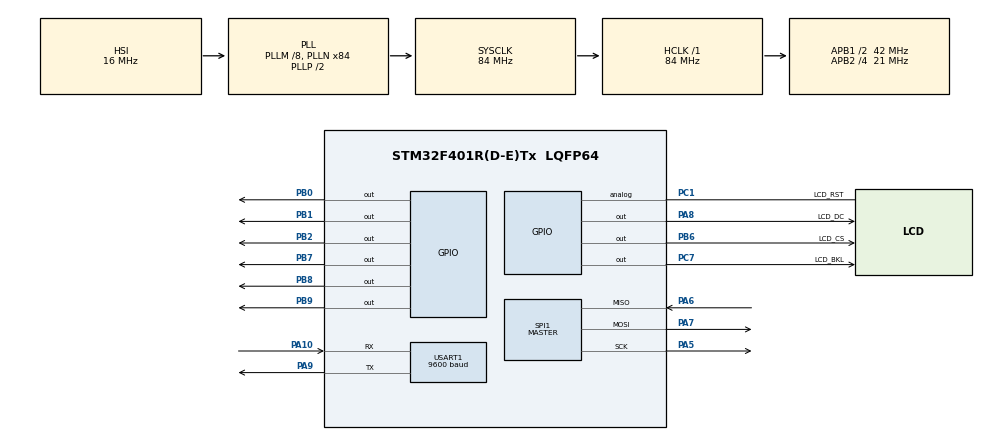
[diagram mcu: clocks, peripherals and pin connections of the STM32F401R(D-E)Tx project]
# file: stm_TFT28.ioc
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Mcu.Family=STM32F4
PA6.Mode=Full_Duplex_Master
RCC.CortexFreq_Value=84000000
SPI1.VirtualType=VM_MASTER
USART1.BaudRate=9600
PB6.GPIO_Label=LCD_CS
RCC.SYSCLKSource=RCC_SYSCLKSOURCE_PLLCLK
ProjectManager.StackSize=0x400
SPI1.CLKPolarity=SPI_POLARITY_HIGH
PH0\ -\ OSC_IN.Signal=RCC_OSC_IN
SPI1.Direction=SPI_DIRECTION_2LINES
PB1.GPIO_PuPd=GPIO_PULLDOWN
RCC.HCLKFreq_Value=84000000
RCC.APB2TimFreq_Value=42000000
PB6.Signal=GPIO_Output
PC7.Signal=GPIO_Output
RCC.AHBFreq_Value=84000000
RCC.HSE_VALUE=25000000
PB2.Signal=GPIO_Output
PA6.GPIO_PuPd=GPIO_PULLUP
PA5.GPIO_PuPd=GPIO_PULLUP
PB7.Signal=GPIO_Output
PA8.Signal=GPIO_Output
PB2.GPIO_PuPd=GPIO_PULLDOWN
TIM9.Prescaler=21000
Mcu.Package=LQFP64
PB9.Signal=GPIO_Output
PB1.Signal=GPIO_Output
PA6.Signal=SPI1_MISO
PA10.Signal=USART1_RX
PB9.GPIO_PuPd=GPIO_PULLDOWN
RCC.APB2CLKDivider=RCC_HCLK_DIV4
RCC.APB1TimFreq_Value=84000000
PA6.GPIO_Speed=GPIO_SPEED_FREQ_HIGH
NVIC.USART1_IRQn=true\:0\:0\:false\:false\:true\:true\:true
SPI1.BaudRatePrescaler=SPI_BAUDRATEPRESCALER_16
PA8.GPIO_Speed=GPIO_SPEED_FREQ_HIGH
TIM9.Period=1
PA5.Mode=Full_Duplex_Master
PB7.GPIO_PuPd=GPIO_PULLDOWN
PA7.Mode=Full_Duplex_Master
PA10.Mode=Asynchronous
PB6.GPIO_PuPd=GPIO_PULLUP
PH1\ -\ OSC_OUT.Mode=HSE-External-Oscillator
PB8.GPIO_PuPd=GPIO_PULLDOWN
SPI1.CLKPhase=SPI_PHASE_2EDGE
RCC.APB1CLKDivider=RCC_HCLK_DIV2
PA0-WKUP.Signal=SYS_WKUP
PA0-WKUP.Mode=SYS_WakeUp0
PA9.Mode=Asynchronous
PH0\ -\ OSC_IN.Mode=HSE-External-Oscillator
PA8.GPIO_Label=LCD_DC
ProjectManager.TargetToolchain=SW4STM32
PA9.Signal=USART1_TX
PC7.GPIO_PuPd=GPIO_PULLUP
RCC.LSE_VALUE=32768
PA7.GPIO_PuPd=GPIO_PULLUP
PA5.Signal=SPI1_SCK
PH1\ -\ OSC_OUT.Signal=RCC_OSC_OUT
board=stm_TFT28
PC7.GPIO_Speed=GPIO_SPEED_FREQ_HIGH
RCC.VCOOutputFreq_Value=168000000
PA7.GPIO_Speed=GPIO_SPEED_FREQ_HIGH
VP_TIM9_VS_ClockSourceINT.Mode=Internal
RCC.APB2Freq_Value=21000000
SPI1.CRCCalculation=SPI_CRCCALCULATION_DISABLE
SPI1.Mode=SPI_MODE_MASTER
PC1.GPIO_Label=LCD_RST
Mcu.Name=STM32F401R(D-E)Tx
TIM9.ClockDivision=TIM_CLOCKDIVISION_DIV1
NVIC.TIM1_BRK_TIM9_IRQn=true\:0\:0\:false\:false\:true\:true\:true
PC7.GPIO_Label=LCD_BKL
RCC.48MHZClocksFreq_Value=42000000
RCC.SYSCLKFreq_VALUE=84000000
USART1.VirtualMode=VM_ASYNC
ProjectManager.HeapSize=0x200
RCC.HSI_VALUE=16000000
PA8.GPIO_PuPd=GPIO_PULLUP
PA5.GPIO_Speed=GPIO_SPEED_FREQ_HIGH
NVIC.PriorityGroup=NVIC_PRIORITYGROUP_4
RCC.PLLM=8
RCC.PLLN=84
PB8.Signal=GPIO_Output
PB6.GPIO_Speed=GPIO_SPEED_FREQ_HIGH
RCC.APB1Freq_Value=42000000
PB0.Signal=GPIO_Output
PC1.Signal=GPIO_Analog
PB0.GPIO_PuPd=GPIO_PULLDOWN
PA7.Signal=SPI1_MOSI

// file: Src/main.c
/* USER CODE BEGIN Header */
/**
  ******************************************************************************
  * @file           : main.c
  * @brief          : Main program body
  ******************************************************************************
  * @attention
  *
  * <h2><center>&copy; Copyright (c) 2020 STMicroelectronics.
  * All rights reserved.</center></h2>
  *
  * This software component is licensed by ST under BSD 3-Clause license,
  * the "License"; You may not use this file except in compliance with the
  * License. You may obtain a copy of the License at:
  *                        opensource.org/licenses/BSD-3-Clause
  *
  ******************************************************************************
  */
/* USER CODE END Header */

#include "main.h"

/* USER CODE BEGIN Includes */
#include "main_usercode.h"
/* USER CODE END Includes */

SPI_HandleTypeDef hspi1;

TIM_HandleTypeDef htim9;

UART_HandleTypeDef huart1;

/* USER CODE BEGIN PV */
/* Private variables ---------------------------------------------------------*/

/* USER CODE END PV */

void SystemClock_Config(void);
static void MX_GPIO_Init(void);
static void MX_TIM9_Init(void);
static void MX_SPI1_Init(void);
static void MX_USART1_UART_Init(void);
/* USER CODE BEGIN PFP */
/* Private function prototypes -----------------------------------------------*/

/* USER CODE END PFP */

/* USER CODE BEGIN 0 */
uint8_t GL_PROJECT_NAME[]="PROJECT OF EXPERIMENTS WITH ShareWave TFT 2.8 #1\r\n";
/* USER CODE END 0 */

int main(void)
{

  /* MCU Configuration--------------------------------------------------------*/

  /* Reset of all peripherals, Initializes the Flash interface and the Systick. */
  HAL_Init();

  /* Configure the system clock */
  SystemClock_Config();

  /* Initialize all configured peripherals */
  MX_GPIO_Init();
  MX_TIM9_Init();
  MX_SPI1_Init();
  MX_USART1_UART_Init();

  /* Infinite loop */
  /* USER CODE BEGIN WHILE */
  while (1)
  {
    main_usercode();
    /* USER CODE END WHILE */

  }
}

void SystemClock_Config(void)
{
  RCC_OscInitTypeDef RCC_OscInitStruct = {0};
  RCC_ClkInitTypeDef RCC_ClkInitStruct = {0};

  /** Configure the main internal regulator output voltage
  */
  __HAL_RCC_PWR_CLK_ENABLE();
  __HAL_PWR_VOLTAGESCALING_CONFIG(PWR_REGULATOR_VOLTAGE_SCALE2);
  /** Initializes the CPU, AHB and APB busses clocks
  */
  RCC_OscInitStruct.OscillatorType = RCC_OSCILLATORTYPE_HSI;
  RCC_OscInitStruct.HSIState = RCC_HSI_ON;
  RCC_OscInitStruct.HSICalibrationValue = RCC_HSICALIBRATION_DEFAULT;
  RCC_OscInitStruct.PLL.PLLState = RCC_PLL_ON;
  RCC_OscInitStruct.PLL.PLLSource = RCC_PLLSOURCE_HSI;
  RCC_OscInitStruct.PLL.PLLM = 8;
  RCC_OscInitStruct.PLL.PLLN = 84;
  RCC_OscInitStruct.PLL.PLLP = RCC_PLLP_DIV2;
  RCC_OscInitStruct.PLL.PLLQ = 4;
  if (HAL_RCC_OscConfig(&RCC_OscInitStruct) != HAL_OK)
  {
    Error_Handler();
  }
  /** Initializes the CPU, AHB and APB busses clocks
  */
  RCC_ClkInitStruct.ClockType = RCC_CLOCKTYPE_HCLK|RCC_CLOCKTYPE_SYSCLK
                              |RCC_CLOCKTYPE_PCLK1|RCC_CLOCKTYPE_PCLK2;
  RCC_ClkInitStruct.SYSCLKSource = RCC_SYSCLKSOURCE_PLLCLK;
  RCC_ClkInitStruct.AHBCLKDivider = RCC_SYSCLK_DIV1;
  RCC_ClkInitStruct.APB1CLKDivider = RCC_HCLK_DIV2;
  RCC_ClkInitStruct.APB2CLKDivider = RCC_HCLK_DIV4;

  if (HAL_RCC_ClockConfig(&RCC_ClkInitStruct, FLASH_LATENCY_2) != HAL_OK)
  {
    Error_Handler();
  }
}

static void MX_SPI1_Init(void)
{

  /* SPI1 parameter configuration*/
  hspi1.Instance = SPI1;
  hspi1.Init.Mode = SPI_MODE_MASTER;
  hspi1.Init.Direction = SPI_DIRECTION_2LINES;
  hspi1.Init.DataSize = SPI_DATASIZE_8BIT;
  hspi1.Init.CLKPolarity = SPI_POLARITY_HIGH;
  hspi1.Init.CLKPhase = SPI_PHASE_2EDGE;
  hspi1.Init.NSS = SPI_NSS_SOFT;
  hspi1.Init.BaudRatePrescaler = SPI_BAUDRATEPRESCALER_16;
  hspi1.Init.FirstBit = SPI_FIRSTBIT_MSB;
  hspi1.Init.TIMode = SPI_TIMODE_DISABLE;
  hspi1.Init.CRCCalculation = SPI_CRCCALCULATION_DISABLE;
  hspi1.Init.CRCPolynomial = 10;
  if (HAL_SPI_Init(&hspi1) != HAL_OK)
  {
    Error_Handler();
  }

}

static void MX_TIM9_Init(void)
{

  TIM_ClockConfigTypeDef sClockSourceConfig = {0};

  htim9.Instance = TIM9;
  htim9.Init.Prescaler = 21000;
  htim9.Init.CounterMode = TIM_COUNTERMODE_UP;
  htim9.Init.Period = 1;
  htim9.Init.ClockDivision = TIM_CLOCKDIVISION_DIV1;
  htim9.Init.AutoReloadPreload = TIM_AUTORELOAD_PRELOAD_DISABLE;
  if (HAL_TIM_Base_Init(&htim9) != HAL_OK)
  {
    Error_Handler();
  }
  sClockSourceConfig.ClockSource = TIM_CLOCKSOURCE_INTERNAL;
  if (HAL_TIM_ConfigClockSource(&htim9, &sClockSourceConfig) != HAL_OK)
  {
    Error_Handler();
  }

}

static void MX_USART1_UART_Init(void)
{

  huart1.Instance = USART1;
  huart1.Init.BaudRate = 9600;
  huart1.Init.WordLength = UART_WORDLENGTH_8B;
  huart1.Init.StopBits = UART_STOPBITS_1;
  huart1.Init.Parity = UART_PARITY_NONE;
  huart1.Init.Mode = UART_MODE_TX_RX;
  huart1.Init.HwFlowCtl = UART_HWCONTROL_NONE;
  huart1.Init.OverSampling = UART_OVERSAMPLING_16;
  if (HAL_UART_Init(&huart1) != HAL_OK)
  {
    Error_Handler();
  }

}

static void MX_GPIO_Init(void)
{
  GPIO_InitTypeDef GPIO_InitStruct = {0};

  /* GPIO Ports Clock Enable */
  __HAL_RCC_GPIOH_CLK_ENABLE();
  __HAL_RCC_GPIOC_CLK_ENABLE();
  __HAL_RCC_GPIOA_CLK_ENABLE();
  __HAL_RCC_GPIOB_CLK_ENABLE();

  /*Configure GPIO pin Output Level */
  HAL_GPIO_WritePin(GPIOB, GPIO_PIN_0|GPIO_PIN_1|GPIO_PIN_2|LCD_CS_Pin
                          |GPIO_PIN_7|GPIO_PIN_8|GPIO_PIN_9, GPIO_PIN_RESET);

  /*Configure GPIO pin Output Level */
  HAL_GPIO_WritePin(LCD_BKL_GPIO_Port, LCD_BKL_Pin, GPIO_PIN_RESET);

  /*Configure GPIO pin Output Level */
  HAL_GPIO_WritePin(LCD_DC_GPIO_Port, LCD_DC_Pin, GPIO_PIN_RESET);

  /*Configure GPIO pin : LCD_RST_Pin */
  GPIO_InitStruct.Pin = LCD_RST_Pin;
  GPIO_InitStruct.Mode = GPIO_MODE_ANALOG;
  GPIO_InitStruct.Pull = GPIO_NOPULL;
  HAL_GPIO_Init(LCD_RST_GPIO_Port, &GPIO_InitStruct);

  /*Configure GPIO pins : PB0 PB1 PB2 PB7
                           PB8 PB9 */
  GPIO_InitStruct.Pin = GPIO_PIN_0|GPIO_PIN_1|GPIO_PIN_2|GPIO_PIN_7
                          |GPIO_PIN_8|GPIO_PIN_9;
  GPIO_InitStruct.Mode = GPIO_MODE_OUTPUT_PP;
  GPIO_InitStruct.Pull = GPIO_PULLDOWN;
  GPIO_InitStruct.Speed = GPIO_SPEED_FREQ_LOW;
  HAL_GPIO_Init(GPIOB, &GPIO_InitStruct);

  /*Configure GPIO pin : LCD_BKL_Pin */
  GPIO_InitStruct.Pin = LCD_BKL_Pin;
  GPIO_InitStruct.Mode = GPIO_MODE_OUTPUT_PP;
  GPIO_InitStruct.Pull = GPIO_PULLUP;
  GPIO_InitStruct.Speed = GPIO_SPEED_FREQ_HIGH;
  HAL_GPIO_Init(LCD_BKL_GPIO_Port, &GPIO_InitStruct);

  /*Configure GPIO pin : LCD_DC_Pin */
  GPIO_InitStruct.Pin = LCD_DC_Pin;
  GPIO_InitStruct.Mode = GPIO_MODE_OUTPUT_PP;
  GPIO_InitStruct.Pull = GPIO_PULLUP;
  GPIO_InitStruct.Speed = GPIO_SPEED_FREQ_HIGH;
  HAL_GPIO_Init(LCD_DC_GPIO_Port, &GPIO_InitStruct);

  /*Configure GPIO pin : LCD_CS_Pin */
  GPIO_InitStruct.Pin = LCD_CS_Pin;
  GPIO_InitStruct.Mode = GPIO_MODE_OUTPUT_PP;
  GPIO_InitStruct.Pull = GPIO_PULLUP;
  GPIO_InitStruct.Speed = GPIO_SPEED_FREQ_HIGH;
  HAL_GPIO_Init(LCD_CS_GPIO_Port, &GPIO_InitStruct);

}

void Error_Handler(void)
{
  while(1)
  {
  }
}

/************************ (C) COPYRIGHT STMicroelectronics *****END OF FILE****/
